# SPC1068 register map
File version: 20180100_70611510
CPU: CM3 r2p1, little endian, MPU, no FPU, 4 interrupt priority bits
Registers are 32-bit, read-write, reset 0x0 unless marked. A register's access mark holds for its fields unless they carry their own. Offsets are from the block's base; [hi:lo] are bit positions; {n}, {i} and the like mark numbered series; 'fields as' and 'values as' point back to an identical list.

## GLOBAL
Base 0x4000B000
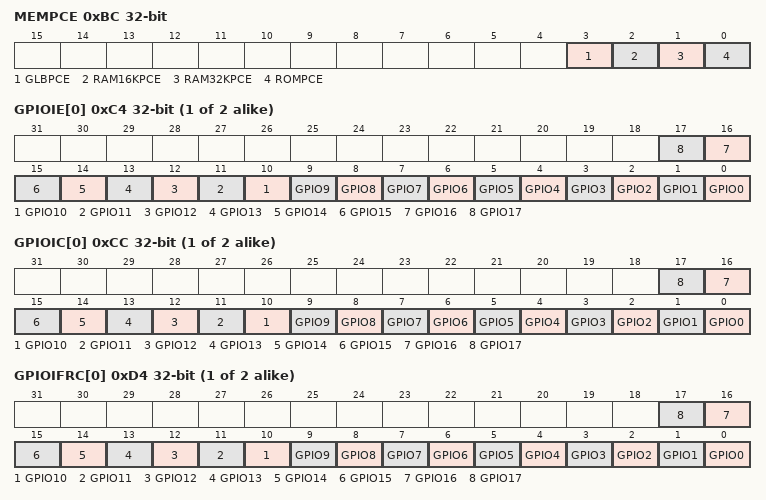
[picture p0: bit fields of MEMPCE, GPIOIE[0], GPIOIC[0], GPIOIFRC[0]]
0xBC MEMPCE — Memory Parity Check Enable Register
  [3] GLBPCE — Global parity check enable
    0=DISABLE (Disable parity check for all memories); 1=ENABLE (Prerequisite to enable parity check for all memories)
  [2] RAM16KPCE — 16K RAM parity check enable
    0=DISABLE (Disable parity check for 16K RAM); 1=ENABLE (Enable parity check for 16K RAM when GLBPCE=1)
  [1] RAM32KPCE — 32K RAM parity check enable
    0=DISABLE (Disable parity check for 32K RAM); 1=ENABLE (Enable parity check for 32K RAM when GLBPCE=1)
  [0] ROMPCE — ROM parity check enable
    0=DISABLE (Disable parity check for ROM); 1=ENABLE (Enable parity check for ROM when GLBPCE=1)
{0xC4+4i} GPIOIE[{i}] (i=0..1) — GPIO Interrupt Enable Register 0
  [all] fields
    0=DISABLE (Disable interrupt); 1=ENABLE (Enable interrupt)
  [n] GPIO{n} (n=0..17) — GPIO{n} interrupt enable
{0xCC+4i} GPIOIC[{i}] (i=0..1) — GPIO Interrupt Clear Register 0
  [all] fields
    0=RELEASE (Release the clear); 1=CLEAR (Clear the interrupt)
  [n] GPIO{n} (n=0..17) — GPIO{n} interrupt clear
{0xD4+4i} GPIOIFRC[{i}] (i=0..1) — GPIO Interrupt Force Register 0
  [all] fields
    0=RELEASE (Release the force); 1=FORCE (Force an interrupt)
  [n] GPIO{n} (n=0..17) — GPIO{n} interrupt force
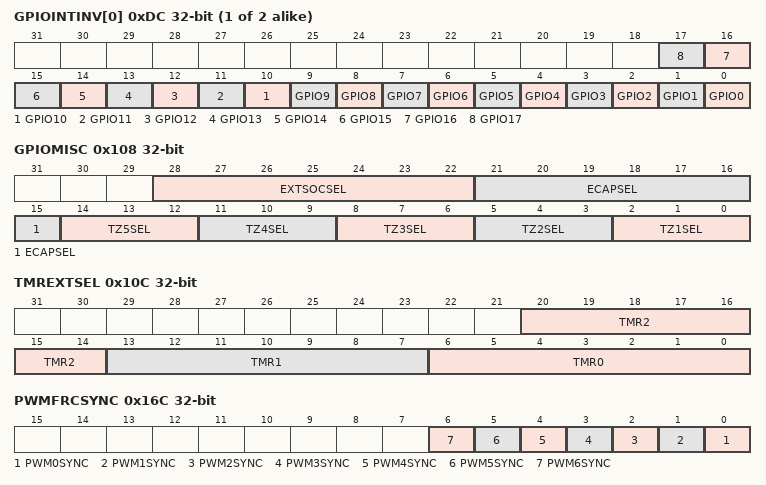
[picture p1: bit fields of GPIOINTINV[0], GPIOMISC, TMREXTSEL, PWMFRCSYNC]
{0xDC+4i} GPIOINTINV[{i}] (i=0..1) — GPIO Interrupt Polarity Inversion Register 0
  [all] fields
    0=HIGH_ACTIVE (Resume polarity (interrupt when high)); 1=LOW_ACTIVE (Invert polarity (interrupt when low))
  [n] GPIO{n} (n=0..17) — GPIO{n} interrupt polarity inversion
0x108 GPIOMISC — GPIO Miscellaneous Control Register
  [28:22] EXTSOCSEL — EXTSOC event source select
    0=NO_EVENT (0 (No EXTSOC event)); {v}=GPIO{v-1} (v=1..36)
  [21:15] ECAPSEL — ECAP event source select
    0=NO_EVENT (0 (No ECAP event)); {v}=GPIO{v-1} (v=1..36)
  [3n-1:3n-3] TZ{n}SEL (n=1..5) — TZ{n} event source select
    0=NO_EVENT (0 (No TZ{n} event)); 1=GPIO{n-1}; 2=GPIO{n+4}; 3=GPIO{n+9}; 4=GPIO{n+14}; 5=GPIO{n+19}; 6=GPIO{n+24}; 7=GPIO{n+29}
0x10C TMREXTSEL — Timer External Event Select Register
  [20:14] TMR2 — TIMER2 event source select
    0=NO_EVENT (0 (No TIMER2 event)); {v}=GPIO{v-1} (v=1..36)
  [13:7] TMR1 — TIMER1 event source select
    0=NO_EVENT (0 (No TIMER1 event)); {v}=GPIO{v-1} (v=1..36)
  [6:0] TMR0 — TIMER0 event source select
    0=NO_EVENT (0 (No TIMER0 event)); {v}=GPIO{v-1} (v=1..36)
0x16C PWMFRCSYNC wo — Global PWM Force Synchronization Register
  [n] PWM{n}SYNC (n=0..6) — Software forced synchronization on PWM{n}
    0=NO_EFFECT (Write a 0 has no effect. Always readback 0); 1=ENABLE (Write a 1 will force a SYNC event on PWM{n}. This bit is self-cleared)

## CRC — NOEN
Base 0x41000000
0x00 CRCIF ro — CRC Interrupt Flag Register
  [0] DONE — CRC calculation done interrupt status after mask
    0=NOT_OCCUR (Interrupt is not occurred); 1=OCCUR (Interrupt is occurred)
0x04 CRCRAWIF ro — CRC Raw Interrupt Flag Register
  [0] DONE — CRC calculation done interrupt raw status regardless of mask
    values as CRCIF.DONE
0x08 CRCIC wo — CRC Interrupt Clear Register
  [0] DONE — Clearance of CRCIF[0] and CRCRAWIF[0]
    0=NO_EFFECT (None); 1=CLEAR_FLAG (Write "1" will generate a single-cycle pulse that clears both CRCIF[0] and CRCRAWIF[0])
0x0C CRCINTMSK reset 0x1 — CRC Interrupt Mask Register
  [0] MSKDONE — Mask of interrupt
    0=UNMASK (Enable generation of IRQ and corresponding CRCIF[0]); 1=MASK (Disable generation of IRQ and corresponding CRCIF[0])
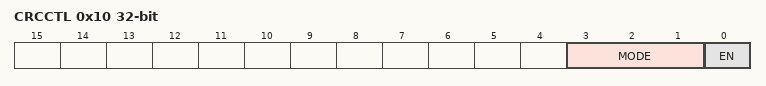
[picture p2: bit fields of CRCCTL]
0x10 CRCCTL — CRC Control Register
  [3:1] MODE — CRC mode select
    0=16_CCITT (x**16+x**12+x**5+1 (CRC-16-CCITT, CRC-CCITT)); 1=16_IBM (x**16+x**15+x**2+1 (CRC-16, CRC-16-IBM, CRC-16-ANSI)); 2=16_T10_DIF (x**16+x**15+x**11+x**9+x**8+x**7+x**5+x**4+x**2+x+1 (CRC-16-T10-DIF)); 3=IEEE802_3 (x**32+x**26+x**23+x**22+x**16+x**12+x**11+x**10+x**8+x**7+x**5+x**4+x**2+x+1 (CRC-32-IEEE802.3)); 4=16_DNP (x**16+x**13+x**12+x**11+x**10+x**8+x**6+x**5+x**2+1(CRC-16-DNP))
  [0] EN — CRC calculate enable
    0=DISABLE (Disable CRC calculation); 1=ENABLE (Enable CRC calculation, it is automatically cleared when the CRC calculation is finished)
0x14 CRCSTRLEN — CRC Stream Length Register
  [31:0] VAL — Input stream length minus 1(in unit of byte)
0x18 CRCSTRIN — CRC Stream Input Register
  [31:0] VAL — Stream Input data register
0x1C CRCRESULT ro
  [31:0] VAL — CRC calculation result
